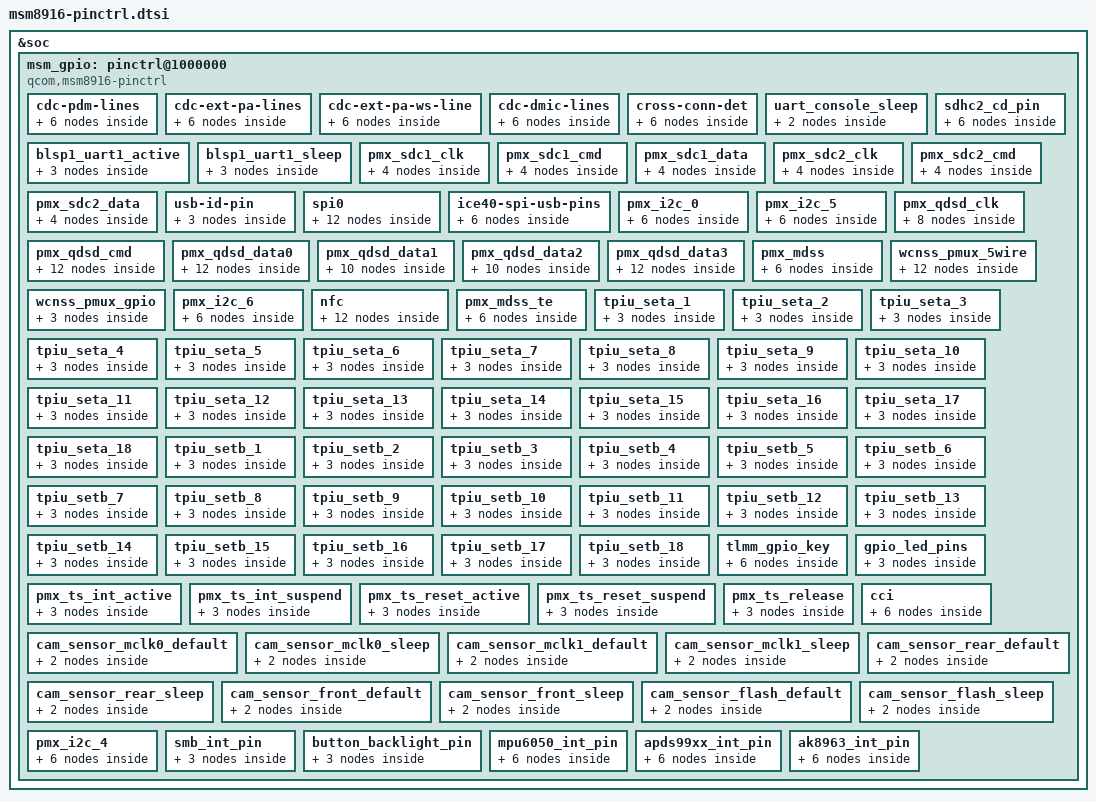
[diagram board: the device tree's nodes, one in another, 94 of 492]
/* Copyright (c) 2013-2015, The Linux Foundation. All rights reserved.
 *
 * This program is free software; you can redistribute it and/or modify
 * it under the terms of the GNU General Public License version 2 and
 * only version 2 as published by the Free Software Foundation.
 *
 * This program is distributed in the hope that it will be useful,
 * but WITHOUT ANY WARRANTY; without even the implied warranty of
 * MERCHANTABILITY or FITNESS FOR A PARTICULAR PURPOSE.  See the
 * GNU General Public License for more details.
 */

&soc {
	msm_gpio: pinctrl@1000000 {
		compatible = "qcom,msm8916-pinctrl";
		reg = <0x1000000 0x300000>;
		interrupts = <0 208 0>;
		gpio-controller;
		#gpio-cells = <2>;
		interrupt-controller;
		#interrupt-cells = <2>;

		cdc-pdm-lines {
			cdc_pdm_lines_act: pdm_lines_on {
				mux {
					pins = "gpio63", "gpio64", "gpio65",
						"gpio66", "gpio67", "gpio68";
					function = "cdc_pdm0";
				};

				config {
					pins = "gpio63", "gpio64", "gpio65",
						"gpio66", "gpio67", "gpio68";
					drive-strength = <8>;
					bias-pull-none;
				};
			};
			cdc_pdm_lines_sus: pdm_lines_off {
				mux {
					pins = "gpio113", "gpio114",
						"gpio115", "gpio116";
					function = "cdc_pdm0";
				};

				config {
					pins = "gpio113", "gpio114",
						"gpio115", "gpio116";
					drive-strength = <2>;
					bias-pull-down;
				};
			};
		};

		cdc-ext-pa-lines {
			cdc_ext_pa_act: ext_pa_on {
				mux {
					pins = "gpio113", "gpio114",
						"gpio115", "gpio116";
					function = "cdc_pdm0";
				};

				config {
					pins = "gpio113", "gpio114",
						"gpio115", "gpio116";
					drive-strength = <8>;
				};
			};
			cdc_ext_pa_sus: ext_pa_off {
				mux {
					pins = "gpio113", "gpio114",
						"gpio115", "gpio116";
					function = "cdc_pdm0";
				};

				config {
					pins = "gpio113", "gpio114",
						"gpio115", "gpio116";
					drive-strength = <2>;
					bias-disable;
				};
			};
		};

		cdc-ext-pa-ws-line {
			cdc_ext_pa_ws_act: ext_pa_on {
				mux {
					pins = "gpio110";
					function = "cdc_pdm0";
				};

				config {
					pins = "gpio110";
					drive-strength = <8>;
				};
			};
			cdc_ext_pa_ws_sus: ext_pa_off {
				mux {
					pins = "gpio110";
					function = "cdc_pdm0";
				};

				config {
					pins = "gpio110";
					drive-strength = <2>;
					bias-disable;
				};
			};
		};

		cdc-dmic-lines {
			cdc_dmic_lines_act: dmic_lines_on {
				mux {
					pins = "gpio0", "gpio1";
					function = "gpio";
				};

				config {
					pins = "gpio0", "gpio1";
					drive-strength = <8>;
				};
			};
			cdc_dmic_lines_sus: dmic_lines_off {
				mux {
					pins = "gpio0", "gpio1";
					function = "gpio";
				};

				config {
					pins = "gpio0", "gpio1";
					drive-strength = <2>;
					bias-disable;
				};
			};
		};

		cross-conn-det {
			cross_conn_det_act: lines_on {
				mux {
					pins = "gpio120";
					function = "gpio";
				};

				config {
					pins = "gpio120";
					drive-strength = <8>;
					output-low;
					bias-pull-down;
				};
			};

			cross_conn_det_sus: lines_off {
				mux {
					pins = "gpio120";
					function = "gpio";
				};

				config {
					pins = "gpio120";
					drive-strength = <2>;
					bias-disable;
				};
			};
		};

		uart_console_sleep: uart_console_sleep {
			mux {
				pins = "gpio4", "gpio5";
				function = "blsp_uart1";
			};
			config {
				pins = "gpio4", "gpio5";
				drive-strength = <2>;
				bias-pull-down;
			};
		};

		blsp1_uart1_active {
			hsuart_active: hsuart_active {
				mux {
					pins = "gpio0", "gpio1", "gpio2", "gpio3";
					function = "blsp_uart1";
				};
				config {
					pins = "gpio0", "gpio1", "gpio2", "gpio3";
					drive-strength = <16>;
					bias-pull-down;
				};
			};
		};

		blsp1_uart1_sleep {
			hsuart_sleep: sleep {
				mux {
					pins = "gpio0", "gpio1", "gpio2", "gpio3";
					function = "blsp_uart1";
				};
				config {
					pins = "gpio0", "gpio1", "gpio2", "gpio3";
					drive-strength = <2>;
					bias-disable;
				};
			};
		};

		sdhc2_cd_pin {
			sdc2_cd_on: cd_on {
				mux {
					pins = "gpio38";
					function = "gpio";
				};
				config {
					pins = "gpio38";
					drive-strength = <2>;
					bias-pull-up;
				};
			};
			sdc2_cd_off: cd_off {
				mux {
					pins = "gpio38";
					function = "gpio";
				};
				config {
					pins = "gpio38";
					drive-strength = <2>;
					bias-disable;
				};
			};
		};

		/* SDC pin type */
		pmx_sdc1_clk {
			sdc1_clk_on: sdc1_clk_on {
				config {
					pins = "sdc1_clk";
					bias-disable; /* NO pull */
					drive-strength = <16>; /* 16 MA */
				};
			};
			sdc1_clk_off: sdc1_clk_off {
				config {
					pins = "sdc1_clk";
					bias-disable; /* NO pull */
					drive-strength = <2>; /* 2 MA */
				};
			};
		};

		pmx_sdc1_cmd {
			sdc1_cmd_on: sdc1_cmd_on {
				config {
					pins = "sdc1_cmd";
					bias-pull-up; /* pull up */
					drive-strength = <10>; /* 10 MA */
				};
			};
			sdc1_cmd_off: sdc1_cmd_off {
				config {
					pins = "sdc1_cmd";
					bias-pull-up; /* pull up */
					drive-strength = <2>; /* 2 MA */
				};
			};
		};

		pmx_sdc1_data {
			sdc1_data_on: sdc1_data_on {
				config {
					pins = "sdc1_data";
					bias-pull-up; /* pull up */
					drive-strength = <10>; /* 10 MA */
				};
			};
			sdc1_data_off: sdc1_data_off {
				config {
					pins = "sdc1_data";
					bias-pull-up; /* pull up */
					drive-strength = <2>; /* 2 MA */
				};
			};
		};

		pmx_sdc2_clk {
			sdc2_clk_on: sdc2_clk_on {
				config {
					pins = "sdc2_clk";
					drive-strength = <16>; /* 16 MA */
					bias-disable; /* NO pull */
				};
			};
			sdc2_clk_off: sdc2_clk_off {
				config {
					pins = "sdc2_clk";
					bias-disable; /* NO pull */
					drive-strength = <2>; /* 2 MA */
				};
			};
		};

		pmx_sdc2_cmd {
			sdc2_cmd_on: sdc2_cmd_on {
				config {
					pins = "sdc2_cmd";
					bias-pull-up; /* pull up */
					drive-strength = <10>; /* 10 MA */
				};
			};
			sdc2_cmd_off: sdc2_cmd_off {
				config {
					pins = "sdc2_cmd";
					bias-pull-up; /* pull up */
					drive-strength = <2>; /* 2 MA */
				};
			};
		};

		pmx_sdc2_data {
			sdc2_data_on: sdc2_data_on {
				config {
					pins = "sdc2_data";
					bias-pull-up; /* pull up */
					drive-strength = <10>; /* 10 MA */
				};
			};
			sdc2_data_off: sdc2_data_off {
				config {
					pins = "sdc2_data";
					bias-pull-up; /* pull up */
					drive-strength = <2>; /* 2 MA */
				};
			};
		};

		usb-id-pin {
			usbid_default: usbid_default {
				mux {
					pins = "gpio110";
					function = "gpio";
				};

				config {
					pins = "gpio110";
					drive-strength = <8>;
					bias-pull-up;
				};
			};
		};

		spi0 {
			spi0_default: spi0_default {
				mux {
					pins = "gpio8", "gpio9",
						"gpio11";
					function = "blsp_spi3";
				};
				config {
					pins = "gpio8", "gpio9",
						"gpio11";
					drive-strength = <12>; /* 12 MA */
					bias-disable; /* No PULL */
				};
			};
			spi0_sleep: spi0_sleep {
				mux {
					pins = "gpio8", "gpio9",
						"gpio11";
					function = "gpio";
				};
				config {
					pins = "gpio8", "gpio9",
						"gpio11";
					drive-strength = <2>; /* 2 MA */
					bias-pull-down; /* pull down */
				};
			};
			spi0_cs0_active: spi0_cs0_active {
				mux {
					pins = "gpio10";
					function = "blsp_spi6";
				};
				config {
					pins = "gpio10";
					drive-strength = <2>;
					bias-disable;
				};
			};
			spi0_cs0_sleep: spi0_cs0_sleep {
				mux {
					pins = "gpio10";
					function = "gpio";
				};
				config {
					pins = "gpio10";
					drive-strength = <2>;
					bias-disable;
				};
			};
		};

		ice40-spi-usb-pins {
			ice40_default: default {
				mux {
					pins = "gpio0", "gpio1",
						"gpio3", "gpio114";
					function = "gpio";
				};
				config {
					pins = "gpio0", "gpio1",
						"gpio3", "gpio114";
					drive-strength = <8>;
					bias-disable;
				};
			};
			ice40_sleep: sleep {
				mux {
					pins = "gpio0", "gpio1",
						"gpio3", "gpio114";
					function = "gpio";
				};
				config {
					pins = "gpio0", "gpio1",
						"gpio3", "gpio114";
					drive-strength = <2>;
					bias-pull-down;
				};
			};
		};

		pmx_i2c_0 {
			i2c_0_active: i2c_0_active {
				mux {
					pins = "gpio7", "gpio6";
					function = "blsp_i2c2";
				};
				config {
					pins = "gpio7", "gpio6";
					drive-strength = <2>; /* 2 MA */
					bias-disable; /* No PULL */
				};
			};
			i2c_0_sleep: i2c_0_sleep {
				mux {
					pins = "gpio7", "gpio6";
					function = "blsp_i2c2";
				};
				config {
					pins = "gpio7", "gpio6";
					drive-strength = <2>; /* 2 MA */
					bias-disable; /* No PULL */
				};
			};
		};

		pmx_i2c_5 {
			i2c_5_active: i2c_0_active {
				mux {
					pins = "gpio19", "gpio18";
					function = "blsp_i2c5";
				};
				config {
					pins = "gpio19", "gpio18";
					drive-strength = <2>; /* 2 MA */
					bias-disable; /* No PULL */
				};
			};
			i2c_5_sleep: i2c_0_sleep {
				mux {
					pins = "gpio19", "gpio18";
					function = "blsp_i2c5";
				};
				config {
					pins = "gpio19", "gpio18";
					drive-strength = <2>; /* 2 MA */
					bias-disable; /* No PULL */
				};
			};
		};

		/* QDSD pin type */
		pmx_qdsd_clk {
			qdsd_clk_sdcard: clk_sdcard {
				config {
					pins = "qdsd_clk";
					bias-disable; /* NO pull */
					drive-strength = <7>; /* 7 MA */
				};
			};
			qdsd_clk_trace: clk_trace {
				config {
					pins = "qdsd_clk";
					bias-pull-down; /* pull down */
					drive-strength = <0>; /* 0 MA */
				};
			};
			qdsd_clk_swdtrc: clk_swdtrc {
				config {
					pins = "qdsd_clk";
					bias-pull-down; /* pull down */
					drive-strength = <0>; /* 0 MA */
				};
			};
			qdsd_clk_spmi: clk_spmi {
				config {
					pins = "qdsd_clk";
					bias-pull-down; /* pull down */
					drive-strength = <0>; /* 0 MA */
				};
			};
		};

		pmx_qdsd_cmd {
			qdsd_cmd_sdcard: cmd_sdcard {
				config {
					pins = "qdsd_cmd";
					bias-pull-down; /* pull down */
					drive-strength = <3>; /* 3 MA */
				};
			};
			qdsd_cmd_trace: cmd_trace {
				config {
					pins = "qdsd_cmd";
					bias-pull-down; /* pull down */
					drive-strength = <0>; /* 0 MA */
				};
			};
			qdsd_cmd_swduart: cmd_uart {
				config {
					pins = "qdsd_cmd";
					bias-pull-up; /* pull up */
					drive-strength = <0>; /* 0 MA */
				};
			};
			qdsd_cmd_swdtrc: cmd_swdtrc {
				config {
					pins = "qdsd_cmd";
					bias-pull-up; /* pull up */
					drive-strength = <0>; /* 0 MA */
				};
			};
			qdsd_cmd_jtag: cmd_jtag {
				config {
					pins = "qdsd_cmd";
					bias-disable; /* NO pull */
					drive-strength = <3>; /* 3 MA */
				};
			};
			qdsd_cmd_spmi: cmd_spmi {
				config {
					pins = "qdsd_cmd";
					bias-pull-down; /* pull down */
					drive-strength = <4>; /* 4 MA */
				};
			};
		};

		pmx_qdsd_data0 {
			qdsd_data0_sdcard: data0_sdcard {
				config {
					pins = "qdsd_data0";
					bias-pull-down; /* pull down */
					drive-strength = <3>; /* 3 MA */
				};
			};
			qdsd_data0_trace: data0_trace {
				config {
					pins = "qdsd_data0";
					bias-pull-down; /* pull down */
					drive-strength = <3>; /* 3 MA */
				};
			};
			qdsd_data0_swduart: data0_uart {
				config {
					pins = "qdsd_data0";
					bias-pull-down; /* pull down */
					drive-strength = <0>; /* 0 MA */
				};
			};
			qdsd_data0_swdtrc: data0_swdtrc {
				config {
					pins = "qdsd_data0";
					bias-pull-down; /* pull down */
					drive-strength = <0>; /* 0 MA */
				};
			};
			qdsd_data0_jtag: data0_jtag {
				config {
					pins = "qdsd_data0";
					bias-pull-up; /* pull up */
					drive-strength = <0>; /* 0 MA */
				};
			};
			qdsd_data0_spmi: data0_spmi {
				config {
					pins = "qdsd_data0";
					bias-pull-down; /* pull down */
					drive-strength = <0>; /* 0 MA */
				};
			};
		};

		pmx_qdsd_data1 {
			qdsd_data1_sdcard: data1_sdcard {
				config {
					pins = "qdsd_data1";
					bias-pull-down; /* pull down */
					drive-strength = <3>; /* 3 MA */
				};
			};
			qdsd_data1_trace: data1_trace {
				config {
					pins = "qdsd_data1";
					bias-pull-down; /* pull down */
					drive-strength = <3>; /* 3 MA */
				};
			};
			qdsd_data1_swduart: data1_uart {
				config {
					pins = "qdsd_data1";
					bias-pull-down; /* pull down */
					drive-strength = <0>; /* 0 MA */
				};
			};
			qdsd_data1_swdtrc: data1_swdtrc {
				config {
					pins = "qdsd_data1";
					bias-pull-down; /* pull down */
					drive-strength = <0>; /* 0 MA */
				};
			};
			qdsd_data1_jtag: data1_jtag {
				config {
					pins = "qdsd_data1";
					bias-pull-down; /* pull down */
					drive-strength = <0>; /* 0 MA */
				};
			};
		};

		pmx_qdsd_data2 {
			qdsd_data2_sdcard: data2_sdcard {
				config {
					pins = "qdsd_data2";
					bias-pull-down; /* pull down */
					drive-strength = <3>; /* 3 MA */
				};
			};
			qdsd_data2_trace: data2_trace {
				config {
					pins = "qdsd_data2";
					bias-pull-down; /* pull down */
					drive-strength = <3>; /* 3 MA */
				};
			};
			qdsd_data2_swduart: data2_uart {
				config {
					pins = "qdsd_data2";
					bias-pull-down; /* pull down */
					drive-strength = <0>; /* 0 MA */
				};
			};
			qdsd_data2_swdtrc: data2_swdtrc {
				config {
					pins = "qdsd_data2";
					bias-pull-down; /* pull down */
					drive-strength = <0>; /* 0 MA */
				};
			};
			qdsd_data2_jtag: data2_jtag {
				config {
					pins = "qdsd_data2";
					bias-pull-up; /* pull up */
					drive-strength = <3>; /* 3 MA */
				};
			};
		};

		pmx_qdsd_data3 {
			qdsd_data3_sdcard: data3_sdcard {
				config {
					pins = "qdsd_data3";
					bias-pull-down; /* pull down */
					drive-strength = <3>; /* 3 MA */
				};
			};
			qdsd_data3_trace: data3_trace {
				config {
					pins = "qdsd_data3";
					bias-pull-down; /* pull down */
					drive-strength = <3>; /* 3 MA */
				};
			};
			qdsd_data3_swduart: data3_uart {
				config {
					pins = "qdsd_data3";
					bias-pull-up; /* pull up */
					drive-strength = <0>; /* 0 MA */
				};
			};
			qdsd_data3_swdtrc: data3_swdtrc {
				config {
					pins = "qdsd_data3";
					bias-pull-up; /* pull up */
					drive-strength = <0>; /* 0 MA */
				};
			};
			qdsd_data3_jtag: data3_jtag {
				config {
					pins = "qdsd_data3";
					bias-pull-up; /* pull up */
					drive-strength = <0>; /* 0 MA */
				};
			};
			qdsd_data3_spmi: data3_spmi {
				config {
					pins = "qdsd_data3";
					bias-pull-down; /* pull down */
					drive-strength = <3>; /* 3 MA */
				};
			};
		};

		pmx_mdss: pmx_mdss {
			mdss_dsi_active: mdss_dsi_active {
				mux {
					pins = "gpio97", "gpio25", "gpio98";
					function = "gpio";
				};

				config {
					drive-strength = <8>; /* 8 mA */
					bias-disable = <0>; /* no pull */
				};
			};

			mdss_dsi_suspend: mdss_dsi_suspend {
				mux {
					pins = "gpio97", "gpio25", "gpio98";
					function = "gpio";
				};

				config {
					drive-strength = <2>; /* 2 mA */
					bias-pull-down; /* pull down */
				};
			};
		};

		wcnss_pmux_5wire: wcnss_pmux_5wire {
			wcnss_default: wcnss_default {
				wcss_wlan2 {
					pins = "gpio40";
					function = "wcss_wlan2";
				};
				wcss_wlan1 {
					pins = "gpio41";
					function = "wcss_wlan1";
				};
				wcss_wlan0 {
					pins = "gpio42";
					function = "wcss_wlan0";
				};
				wcss_wlan {
					pins = "gpio43", "gpio44";
					function = "wcss_wlan";
				};
				config {
					pins = "gpio40", "gpio41",
						"gpio42", "gpio43",
						"gpio44";
					drive-strength = <6>; /* 6 MA */
					bias-pull-up; /* PULL UP */
				};
			};

			wcnss_sleep: wcnss_sleep {
				wcss_wlan2 {
					pins = "gpio40";
					function = "wcss_wlan2";
				};
				wcss_wlan1 {
					pins = "gpio41";
					function = "wcss_wlan1";
				};
				wcss_wlan0 {
					pins = "gpio42";
					function = "wcss_wlan0";
				};
				wcss_wlan {
					pins = "gpio43", "gpio44";
					function = "wcss_wlan";
				};

				config {
					pins = "gpio40", "gpio41",
						"gpio42", "gpio43",
						"gpio44";
					drive-strength = <2>; /* 2 MA */
					bias-pull-down; /* PULL Down */
				};
			};
		};

		wcnss_pmux_gpio: wcnss_pmux_gpio {
			wcnss_gpio_default: wcnss_gpio_default {
				mux {
					pins = "gpio40", "gpio41",
						"gpio42", "gpio43",
						"gpio44";
					function = "gpio";
				};

				config {
					pins = "gpio40", "gpio41",
						"gpio42", "gpio43",
						"gpio44";
					drive-strength = <6>; /* 6 MA */
					bias-pull-up; /* PULL UP */
				};
			};
		};

		pmx_i2c_6 {
			i2c_6_active: i2c_6_active {
				mux {
					pins = "gpio22", "gpio23";
					function = "blsp_i2c6";
				};
				config {
					pins = "gpio22", "gpio23";
					drive-strength = <2>; /* 2 MA */
					bias-disable; /* No PULL */
				};
			};
			i2c_6_sleep: i2c_6_sleep {
				mux {
					pins = "gpio22", "gpio23";
					function = "blsp_i2c6";
				};
				config {
					pins = "gpio22", "gpio23";
					drive-strength = <2>; /* 2 MA */
					bias-disable; /* No PULL */
				};
			};
		};


		nfc {
			nfc_int_active: nfc_int_active {
				mux {
					pins = "gpio21";
					function = "gpio";
				};
				config {
					pins = "gpio21";
					drive-strength = <6>;
					bias-pull-up;
				};
			};

			nfc_int_suspend: nfc_int_suspend {
				mux {
					pins = "gpio21";
					function = "gpio";
				};
				config {
					pins = "gpio21";
					drive-strength = <6>;
					bias-pull-up;
				};
			};

			nfc_disable_active: nfc_disable_active {
				mux {
					pins = "gpio20";
					function = "gpio";
				};
				config {
					pins = "gpio20";
					drive-strength = <6>;
					bias-pull-up;
				};
			};

			nfc_disable_suspend: nfc_disable_suspend {
				mux {
					pins = "gpio20";
					function = "gpio";
				};
				config {
					pins = "gpio20";
					drive-strength = <6>;
					bias-disable;
				};
			};
		};

		pmx_mdss_te {
			mdss_te_active: mdss_te_active {
				mux {
					pins = "gpio24";
					function = "mdp_vsync";
				};

				config {
					drive-strength = <2>; /* 2 mA */
					bias-pull-down; /* pull down */
				};
			};

			mdss_te_suspend: mdss_te_suspend {
				mux {
					pins = "gpio24";
					function = "mdp_vsync";
				};

				config {
					drive-strength = <2>; /* 2 mA */
					bias-pull-down; /* pull down */
				};
			};
		};

		/* CoreSight */
		tpiu_seta_1 {
			seta_1: seta {
				mux {
					pins = "gpio8";
					function = "qdss_traceclk_a";
				};
				config {
					pins = "gpio8";
					drive-strength = <16>;
					bias-disable;
				};
			};
		};

		tpiu_seta_2 {
			seta_2: seta {
				mux {
					pins = "gpio9";
					function = "qdss_tracectl_a";
				};
				config {
					pins = "gpio9";
					drive-strength = <16>;
					bias-disable;
				};
			};
		};

		tpiu_seta_3 {
			seta_3: seta {
				mux {
					pins = "gpio10";
					function = "qdss_tracedata_a";
				};
				config {
					pins = "gpio10";
					drive-strength = <16>;
					bias-disable;
				};
			};
		};

		tpiu_seta_4 {
			seta_4: seta {
				mux {
					pins = "gpio39";
					function = "qdss_tracedata_a";
				};
				config {
					pins = "gpio39";
					drive-strength = <16>;
					bias-disable;
				};
			};
		};

		tpiu_seta_5 {
			seta_5: seta {
				mux {
					pins = "gpio40";
					function = "qdss_tracedata_a";
				};
				config {
					pins = "gpio40";
					drive-strength = <16>;
					bias-disable;
				};
			};
		};

		tpiu_seta_6 {
			seta_6: seta {
				mux {
					pins = "gpio41";
					function = "qdss_tracedata_a";
				};
				config {
					pins = "gpio41";
					drive-strength = <16>;
					bias-disable;
				};
			};
		};

		tpiu_seta_7 {
			seta_7: seta {
				mux {
					pins = "gpio42";
					function = "qdss_tracedata_a";
				};
				config {
					pins = "gpio42";
					drive-strength = <16>;
					bias-disable;
				};
			};
		};

		tpiu_seta_8 {
			seta_8: seta {
				mux {
					pins = "gpio43";
					function = "qdss_tracedata_a";
				};
				config {
					pins = "gpio43";
					drive-strength = <16>;
					bias-disable;
				};
			};
		};

		tpiu_seta_9 {
			seta_9: seta {
				mux {
					pins = "gpio45";
					function = "qdss_tracedata_a";
				};
				config {
					pins = "gpio45";
					drive-strength = <16>;
					bias-disable;
				};
			};
		};

		tpiu_seta_10 {
			seta_10: seta {
				mux {
					pins = "gpio46";
					function = "qdss_tracedata_a";
				};
				config {
					pins = "gpio46";
					drive-strength = <16>;
					bias-disable;
				};
			};
		};

		tpiu_seta_11 {
			seta_11: seta {
				mux {
					pins = "gpio47";
					function = "qdss_tracedata_a";
				};
				config {
					pins = "gpio47";
					drive-strength = <16>;
					bias-disable;
				};
			};
		};

		tpiu_seta_12 {
			seta_12: seta {
				mux {
					pins = "gpio48";
					function = "qdss_tracedata_a";
				};
				config {
					pins = "gpio48";
					drive-strength = <16>;
					bias-disable;
				};
			};
		};

		tpiu_seta_13 {
			seta_13: seta {
				mux {
					pins = "gpio62";
					function = "qdss_tracedata_a";
				};
				config {
					pins = "gpio62";
					drive-strength = <16>;
					bias-disable;
				};
			};
		};

		tpiu_seta_14 {
			seta_14: seta {
				mux {
					pins = "gpio69";
					function = "qdss_tracedata_a";
				};
				config {
					pins = "gpio69";
					drive-strength = <16>;
					bias-disable;
				};
			};
		};

		tpiu_seta_15 {
			seta_15: seta {
				mux {
					pins = "gpio112";
					function = "qdss_tracedata_a";
				};
				config {
					pins = "gpio112";
					drive-strength = <16>;
					bias-disable;
				};
			};
		};

		tpiu_seta_16 {
			seta_16: seta {
				mux {
					pins = "gpio113";
					function = "qdss_tracedata_a";
				};
				config {
					pins = "gpio113";
					drive-strength = <16>;
					bias-disable;
				};
			};
		};

		tpiu_seta_17 {
			seta_17: seta {
				mux {
					pins = "gpio114";
					function = "qdss_tracedata_a";
				};
				config {
					pins = "gpio114";
					drive-strength = <16>;
					bias-disable;
				};
			};
		};

		tpiu_seta_18 {
			seta_18: seta {
				mux {
					pins = "gpio115";
					function = "qdss_tracedata_a";
				};
				config {
					pins = "gpio115";
					drive-strength = <16>;
					bias-disable;
				};
			};
		};

		tpiu_setb_1 {
			setb_1: setb {
				mux {
					pins = "gpio4";
					function = "qdss_tracedata_b";
				};
				config {
					pins = "gpio4";
					drive-strength = <16>;
					bias-disable;
				};
			};
		};

		tpiu_setb_2 {
			setb_2: setb {
				mux {
					pins = "gpio5";
					function = "qdss_tracedata_b";
				};
				config {
					pins = "gpio5";
					drive-strength = <16>;
					bias-disable;
				};
			};
		};

		tpiu_setb_3 {
			setb_3: setb {
				mux {
					pins = "gpio26";
					function = "qdss_tracedata_b";
				};
				config {
					pins = "gpio26";
					drive-strength = <16>;
					bias-disable;
				};
			};
		};

		tpiu_setb_4 {
			setb_4: setb {
				mux {
					pins = "gpio27";
					function = "qdss_tracedata_b";
				};
				config {
					pins = "gpio27";
					drive-strength = <16>;
					bias-disable;
				};
			};
		};

		tpiu_setb_5 {
			setb_5: setb {
				mux {
					pins = "gpio28";
					function = "qdss_tracedata_b";
				};
				config {
					pins = "gpio28";
					drive-strength = <16>;
					bias-disable;
				};
			};
		};

		tpiu_setb_6 {
			setb_6: setb {
				mux {
					pins = "gpio29";
					function = "qdss_tracedata_b";
				};
				config {
					pins = "gpio29";
					drive-strength = <16>;
					bias-disable;
				};
			};
		};

		tpiu_setb_7 {
			setb_7: setb {
				mux {
					pins = "gpio30";
					function = "qdss_tracedata_b";
				};
				config {
					pins = "gpio30";
					drive-strength = <16>;
					bias-disable;
				};
			};
		};

		tpiu_setb_8 {
			setb_8: setb {
				mux {
					pins = "gpio31";
					function = "qdss_tracedata_b";
				};
				config {
					pins = "gpio31";
					drive-strength = <16>;
					bias-disable;
				};
			};
		};

		tpiu_setb_9 {
			setb_9: setb {
				mux {
					pins = "gpio32";
					function = "qdss_tracedata_b";
				};
				config {
					pins = "gpio32";
					drive-strength = <16>;
					bias-disable;
				};
			};
		};

		tpiu_setb_10 {
			setb_10: setb {
				mux {
					pins = "gpio33";
					function = "qdss_tracedata_b";
				};
				config {
					pins = "gpio33";
					drive-strength = <16>;
					bias-disable;
				};
			};
		};

		tpiu_setb_11 {
			setb_11: setb {
				mux {
					pins = "gpio34";
					function = "qdss_tracedata_b";
				};
				config {
					pins = "gpio34";
					drive-strength = <16>;
					bias-disable;
				};
			};
		};

		tpiu_setb_12 {
			setb_12: setb {
				mux {
					pins = "gpio35";
					function = "qdss_tracedata_b";
				};
				config {
					pins = "gpio35";
					drive-strength = <16>;
					bias-disable;
				};
			};
		};

		tpiu_setb_13 {
			setb_13: setb {
				mux {
					pins = "gpio36";
					function = "qdss_tracedata_b";
				};
				config {
					pins = "gpio36";
					drive-strength = <16>;
					bias-disable;
				};
			};
		};

		tpiu_setb_14 {
			setb_14: setb {
				mux {
					pins = "gpio37";
					function = "qdss_tracedata_b";
				};
				config {
					pins = "gpio37";
					drive-strength = <16>;
					bias-disable;
				};
			};
		};

		tpiu_setb_15 {
			setb_15: setb {
				mux {
					pins = "gpio110";
					function = "qdss_tracedata_b";
				};
				config {
					pins = "gpio110";
					drive-strength = <16>;
					bias-disable;
				};
			};
		};

		tpiu_setb_16 {
			setb_16: setb {
				mux {
					pins = "gpio111";
					function = "qdss_tracedata_b";
				};
				config {
					pins = "gpio111";
					drive-strength = <16>;
					bias-disable;
				};
			};
		};

		tpiu_setb_17 {
			setb_17: setb {
				mux {
					pins = "gpio120";
					function = "qdss_tracedata_b";
				};
				config {
					pins = "gpio120";
					drive-strength = <16>;
					bias-disable;
				};
			};
		};

		tpiu_setb_18 {
			setb_18: setb {
				mux {
					pins = "gpio121";
					function = "qdss_tracedata_b";
				};
				config {
					pins = "gpio121";
					drive-strength = <16>;
					bias-disable;
				};
			};
		};

		tlmm_gpio_key {
			gpio_key_active: gpio_key_active {
				mux {
					pins = "gpio107", "gpio108", "gpio109";
					function = "gpio";
				};

				config {
					pins = "gpio107", "gpio108", "gpio109";
					drive-strength = <2>;
					bias-pull-up;
				};
			};

			gpio_key_suspend: gpio_key_suspend {
				mux {
					pins = "gpio107", "gpio108", "gpio109";
					function = "gpio";
				};

				config {
					pins = "gpio107", "gpio108", "gpio109";
					drive-strength = <2>;
					bias-pull-up;
				};
			};
		};

		gpio_led_pins {
			gpio_led_off: gpio_led_off {
				mux {
					pins = "gpio8", "gpio9", "gpio10";
					function = "gpio";
				};

				config {
					pins = "gpio8", "gpio9", "gpio10";
					drive-strength = <2>;
					bias-disable;
					output-low;
				};
			};
		};

		/* add pingrp for touchscreen */
		pmx_ts_int_active {
			ts_int_active: ts_int_active {
				mux {
					pins = "gpio13";
					function = "gpio";
				};

				config {
					pins = "gpio13";
					drive-strength = <8>;
					bias-pull-up;
				};
			};
		};

		pmx_ts_int_suspend {
			ts_int_suspend: ts_int_suspend {
				mux {
					pins = "gpio13";
					function = "gpio";
				};

				config {
					pins = "gpio13";
					drive-strength = <2>;
					bias-pull-down;
				};
			};
		};

		pmx_ts_reset_active {
			ts_reset_active: ts_reset_active {
				mux {
					pins = "gpio12";
					function = "gpio";
				};

				config {
					pins = "gpio12";
					drive-strength = <8>;
					bias-pull-up;
				};
			};
		};

		pmx_ts_reset_suspend {
			ts_reset_suspend: ts_reset_suspend {
				mux {
					pins = "gpio12";
					function = "gpio";
				};

				config {
					pins = "gpio12";
					drive-strength = <2>;
					bias-pull-down;
				};
			};
		};

		pmx_ts_release {
			ts_release: ts_release {
				mux {
					pins = "gpio13", "gpio12";
					function = "gpio";
				};

				config {
					pins = "gpio13", "gpio12";
					drive-strength = <2>;
					bias-pull-down;
				};
			};
		};

		cci {
			cci0_default: cci0_default {
				/* cci0 active state */
				mux {
					/* CLK, DATA */
					pins = "gpio29", "gpio30";
					function = "cci_i2c";
				};

				config {
					pins = "gpio29", "gpio30";
					drive-strength = <2>; /* 2 MA */
					bias-disable; /* No PULL */
				};
			};

			cci0_sleep: cci0_sleep {
				/* cci0 suspended state */
				mux {
					/* CLK, DATA */
					pins = "gpio29", "gpio30";
					function = "cci_i2c";
				};

				config {
					pins = "gpio29", "gpio30";
					drive-strength = <2>; /* 2 MA */
					bias-disable; /* No PULL */
				};
			};
		};

		cam_sensor_mclk0_default: cam_sensor_mclk0_default {
			/* MCLK0 */
			mux {
				/* CLK, DATA */
				pins = "gpio26";
				function = "cam_mclk";
			};

			config {
				pins = "gpio26";
				bias-disable; /* No PULL */
				drive-strength = <2>; /* 2 MA */
			};
		};

		cam_sensor_mclk0_sleep: cam_sensor_mclk0_sleep {
			/* MCLK0 */
			mux {
				/* CLK, DATA */
				pins = "gpio26";
				function = "cam_mclk";
			};

			config {
				pins = "gpio26";
				bias-pull-down; /* PULL DOWN */
				drive-strength = <2>; /* 2 MA */
			};
		};

		cam_sensor_mclk1_default: cam_sensor_mclk1_default {
			/* MCLK1 */
			mux {
				/* CLK, DATA */
				pins = "gpio27";
				function = "cam_mclk";
			};

			config {
				pins = "gpio27";
				bias-disable; /* No PULL */
				drive-strength = <2>; /* 2 MA */
			};
		};

		cam_sensor_mclk1_sleep: cam_sensor_mclk1_sleep {
			/* MCLK1 */
			mux {
				/* CLK, DATA */
				pins = "gpio27";
				function = "cam_mclk";
			};

			config {
				pins = "gpio27";
				bias-pull-down; /* PULL DOWN */
				drive-strength = <2>; /* 2 MA */
			};
		};

		cam_sensor_rear_default: cam_sensor_rear_default {
			/* RESET, STANDBY */
			mux {
				pins = "gpio35", "gpio34";
				function = "gpio";
			};

			config {
				pins = "gpio35","gpio34";
				bias-disable; /* No PULL */
				drive-strength = <2>; /* 2 MA */
			};
		};

		cam_sensor_rear_sleep: cam_sensor_rear_sleep {
			/* RESET, STANDBY */
			mux {
				pins = "gpio35","gpio34";
				function = "gpio";
			};

			config {
				pins = "gpio35","gpio34";
				bias-disable; /* No PULL */
				drive-strength = <2>; /* 2 MA */
			};
		};

		cam_sensor_front_default: cam_sensor_front_default {
			/* RESET, STANDBY */
			mux {
				pins = "gpio28", "gpio33";
				function = "gpio";
			};

			config {
				pins = "gpio28", "gpio33";
				bias-disable; /* No PULL */
				drive-strength = <2>; /* 2 MA */
			};
		};

		cam_sensor_front_sleep: cam_sensor_front_sleep {
			/* RESET, STANDBY */
			mux {
				pins = "gpio28", "gpio33";
				function = "gpio";
			};

			config {
				pins = "gpio28", "gpio33";
				bias-disable; /* No PULL */
				drive-strength = <2>; /* 2 MA */
			};
		};

		cam_sensor_flash_default: cam_sensor_flash_default {
		/* FLASH_RESET,FLASH_EN,FLASH_NOW */
			mux {
				pins = "gpio36", "gpio31", "gpio32";
				function = "gpio";
			};
			config {
				pins = "gpio36", "gpio31", "gpio32";
				bias-disable; /* No PULL */
				drive-strength = <2>; /* 2 MA */
			};
		};

		cam_sensor_flash_sleep: cam_sensor_flash_sleep {
			 mux {
				pins = "gpio36", "gpio31", "gpio32";
				function = "gpio";
			};
			config {
				pins = "gpio36", "gpio31", "gpio32";
				bias-disable; /* No PULL */
				drive-strength = <2>; /* 2 MA */
			};
		};

		pmx_i2c_4 {
			i2c_4_active: i2c_4_active {
				mux {
					pins = "gpio14", "gpio15";
					function = "blsp_i2c4";
				};
				config {
					pins = "gpio14", "gpio15";
					drive-strength = <2>; /* 2 MA */
					bias-disable; /* No PULL */
				};
			};
			i2c_4_sleep: i2c_4_sleep {
				mux {
					pins = "gpio14", "gpio15";
					function = "blsp_i2c4";
				};
				config {
					pins = "gpio14", "gpio15";
					drive-strength = <2>; /* 2 MA */
					bias-disable; /* No PULL */
				};
			};
		};

		smb_int_pin {
			smb_int_default: smb_int_default {
				mux {
					pins = "gpio62";
					function ="smb_int";
				};
				config {
					pins = "gpio62";
					drive-strength = <2>;   /* 2 MA */
					bias-pull-up;           /* PULL UP*/
				};
			};
		};

		button_backlight_pin {
			button_backlight_off: button_backlight_off {
				mux {
					pins = "gpio119";
					function ="gpio";
				};
				config {
					pins = "gpio119";
					drive-strength = <2>;   /* 2 MA */
					bias-disable;
					output-low;
				};
			};
		};

		mpu6050_int_pin {
			mpu6050_default: mpu6050_default {
				mux {
					pins = "gpio115";
					function ="gpio";
				};
				config {
					pins = "gpio115";
					drive-strength = <6>;
					bias-pull-up;
				};
			};
			mpu6050_sleep: mpu6050_sleep {
				mux {
					pins = "gpio115";
					function ="gpio";
				};
				config {
					pins = "gpio115";
					drive-strength = <2>;
				};
			};
		};

		apds99xx_int_pin {
			apds99xx_default: apds99xx_default {
				mux {
					pins = "gpio113";
					function ="gpio";
				};
				config {
					pins = "gpio113";
					drive-strength = <6>;
					bias-pull-up;
				};
			};
			apds99xx_sleep: apds99xx_sleep {
				mux {
					pins = "gpio113";
					function ="gpio";
				};
				config {
					pins = "gpio113";
					drive-strength = <2>;
				};
			};
		};

		ak8963_int_pin {
			ak8963_default: ak8963_default {
				mux {
					pins = "gpio69";
					function ="gpio";
				};
				config {
					pins = "gpio69";
					drive-strength = <6>;
					bias-pull-up;
				};
			};
			ak8963_sleep: ak8963_sleep {
				mux {
					pins = "gpio69";
					function ="gpio";
				};
				config {
					pins = "gpio69";
					drive-strength = <2>;
				};
			};
		};
	};
};
